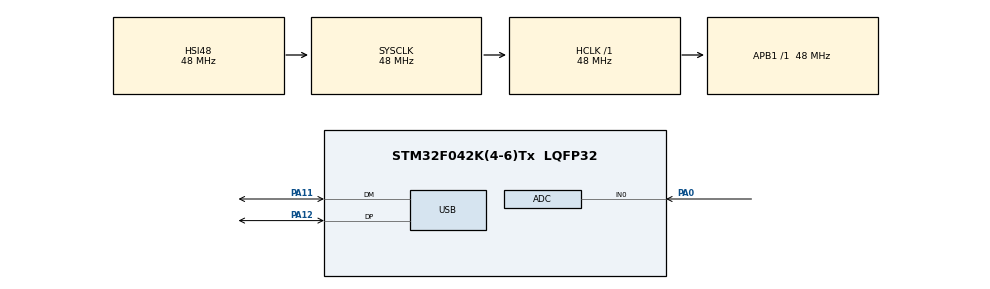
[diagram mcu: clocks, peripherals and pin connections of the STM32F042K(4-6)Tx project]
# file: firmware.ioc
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ADC.ContinuousConvMode=ENABLE
ADC.DMAContinuousRequests=ENABLE
ADC.SamplingTime=ADC_SAMPLETIME_71CYCLES_5
Dma.ADC.0.Direction=DMA_PERIPH_TO_MEMORY
Dma.ADC.0.Instance=DMA1_Channel1
Dma.ADC.0.MemDataAlignment=DMA_MDATAALIGN_HALFWORD
Dma.ADC.0.MemInc=DMA_MINC_ENABLE
Dma.ADC.0.Mode=DMA_CIRCULAR
Dma.ADC.0.PeriphDataAlignment=DMA_PDATAALIGN_HALFWORD
Dma.ADC.0.PeriphInc=DMA_PINC_DISABLE
Dma.ADC.0.Priority=DMA_PRIORITY_HIGH
Dma.Request0=ADC
Mcu.Family=STM32F0
Mcu.Name=STM32F042K(4-6)Tx
Mcu.Package=LQFP32
NVIC.DMA1_Channel1_IRQn=true\:0\:0\:false\:false\:true\:false\:true\:true
NVIC.USB_IRQn=true\:0\:0\:false\:false\:true\:false\:true\:true
PA0.Mode=IN0
PA0.Signal=ADC_IN0
PA11.Mode=Device
PA11.Signal=USB_DM
PA12.Mode=Device
PA12.Signal=USB_DP
PA13.Mode=Serial_Wire
PA13.Signal=SYS_SWDIO
PA14.Mode=Serial_Wire
PA14.Signal=SYS_SWCLK
ProjectManager.HeapSize=0x200
ProjectManager.StackSize=0x400
ProjectManager.TargetToolchain=STM32CubeIDE
RCC.AHBFreq_Value=48000000
RCC.APB1Freq_Value=48000000
RCC.APB1TimFreq_Value=48000000
RCC.HCLKFreq_Value=48000000
RCC.SYSCLKFreq_VALUE=48000000
RCC.SYSCLKSource=RCC_SYSCLKSOURCE_HSI48
USB_DEVICE.CLASS_NAME_FS=HID
USB_DEVICE.MANUFACTURER_STRING=emb3rcia
USB_DEVICE.PRODUCT_STRING_HID_FS=Turnsignals
USB_DEVICE.VirtualMode=Hid
USB_DEVICE.VirtualModeFS=Hid_FS
VP_USB_DEVICE_VS_USB_DEVICE_HID_FS.Mode=HID_FS
board=custom

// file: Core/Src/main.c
/* USER CODE BEGIN Header */
/**
  ******************************************************************************
  * @file           : main.c
  * @brief          : Main program body
  ******************************************************************************
  * @attention
  *
  * Copyright (c) 2026 STMicroelectronics.
  * All rights reserved.
  *
  * This software is licensed under terms that can be found in the LICENSE file
  * in the root directory of this software component.
  * If no LICENSE file comes with this software, it is provided AS-IS.
  *
  ******************************************************************************
  */
/* USER CODE END Header */
#include "main.h"
#include "usb_device.h"

ADC_HandleTypeDef hadc;
DMA_HandleTypeDef hdma_adc;

/* USER CODE BEGIN PV */
// i based this on chatgpt's example barebone code as it is my first stm32 project, but i did NOT copy it line for line, wanted to be transparent
#define ADC_LOW_THRESHOLD 1000
#define ADC_HIGH_THRESHOLD 3000
#define STABLE_COUNT 8
#define KEY_LOW 0x4F
#define KEY_HIGH 0x50

typedef enum {
	ADC_ZONE_MIDDLE = 0,
	ADC_ZONE_LOW,
	ADC_ZONE_HIGH
} adc_zone_t;

static adc_zone_t zone = ADC_ZONE_MIDDLE;
static uint8_t high_count = 0;
static uint8_t low_count  = 0;
static uint8_t middle_count = 0;

uint32_t value_adc;

/* USER CODE END PV */

void SystemClock_Config(void);
static void MX_GPIO_Init(void);
static void MX_DMA_Init(void);
static void MX_ADC_Init(void);

/* USER CODE BEGIN 0 */
void ADC_CheckZone(uint32_t adc)
{
	if (adc > ADC_HIGH_THRESHOLD)
	{
		high_count++;
		low_count = 0;
		middle_count = 0;

		if (high_count >= STABLE_COUNT && zone != ADC_ZONE_HIGH)
		{
			zone = ADC_ZONE_HIGH;
			high_count = 0;
			uint8_t HID_Report[8] = {0};
			HID_Report[2] = KEY_HIGH;
			USBD_HID_SendReport(&hUsbDeviceFS, HID_Report, sizeof(HID_Report));
		    HAL_Delay(10);
		    HID_Report[2] = 0;
		    USBD_HID_SendReport(&hUsbDeviceFS, HID_Report, sizeof(HID_Report));
		    HAL_Delay(10);
		}
	}
	else if (adc < ADC_LOW_THRESHOLD)
	{
		low_count++;
		high_count = 0;
		middle_count = 0;

		if (low_count >= STABLE_COUNT && zone != ADC_ZONE_LOW)
		{
			zone = ADC_ZONE_LOW;
			low_count = 0;
			uint8_t HID_Report[8] = {0};
			HID_Report[2] = KEY_LOW;
			USBD_HID_SendReport(&hUsbDeviceFS, HID_Report, sizeof(HID_Report));
		    HAL_Delay(10);
		    HID_Report[2] = 0;
		    USBD_HID_SendReport(&hUsbDeviceFS, HID_Report, sizeof(HID_Report));
		    HAL_Delay(10);
		}
	}
	else
	{
		middle_count++;
		high_count = 0;
		low_count = 0;

		if (middle_count >= STABLE_COUNT && zone != ADC_ZONE_MIDDLE)
		{
			if (zone == ADC_ZONE_HIGH)
			{
				uint8_t HID_Report[8] = {0};
				HID_Report[2] = KEY_HIGH;
				USBD_HID_SendReport(&hUsbDeviceFS, HID_Report, sizeof(HID_Report));
			    HAL_Delay(10);
			    HID_Report[2] = 0;
			    USBD_HID_SendReport(&hUsbDeviceFS, HID_Report, sizeof(HID_Report));
			    HAL_Delay(10);
			}
			else if (zone == ADC_ZONE_LOW)
			{
				uint8_t HID_Report[8] = {0};
				HID_Report[2] = KEY_LOW;
				USBD_HID_SendReport(&hUsbDeviceFS, HID_Report, sizeof(HID_Report));
				HAL_Delay(10);
				HID_Report[2] = 0;
				USBD_HID_SendReport(&hUsbDeviceFS, HID_Report, sizeof(HID_Report));
				HAL_Delay(10);
			}
			zone = ADC_ZONE_MIDDLE;
			middle_count = 0;

		}
	}
}
/* USER CODE END 0 */

int main(void)
{

  /* MCU Configuration--------------------------------------------------------*/

  /* Reset of all peripherals, Initializes the Flash interface and the Systick. */
  HAL_Init();

  /* Configure the system clock */
  SystemClock_Config();

  /* Initialize all configured peripherals */
  MX_GPIO_Init();
  MX_DMA_Init();
  MX_ADC_Init();
  MX_USB_DEVICE_Init();
  /* USER CODE BEGIN 2 */
  HAL_ADC_Start_DMA(&hadc, &value_adc, 1);
  /* USER CODE END 2 */

  /* Infinite loop */
  /* USER CODE BEGIN WHILE */
  while (1)
  {
	  ADC_CheckZone(value_adc);
	  HAL_Delay(10);
    /* USER CODE END WHILE */

  }
}

void SystemClock_Config(void)
{
  RCC_OscInitTypeDef RCC_OscInitStruct = {0};
  RCC_ClkInitTypeDef RCC_ClkInitStruct = {0};
  RCC_PeriphCLKInitTypeDef PeriphClkInit = {0};

  /** Initializes the RCC Oscillators according to the specified parameters
  * in the RCC_OscInitTypeDef structure.
  */
  RCC_OscInitStruct.OscillatorType = RCC_OSCILLATORTYPE_HSI14|RCC_OSCILLATORTYPE_HSI48;
  RCC_OscInitStruct.HSI48State = RCC_HSI48_ON;
  RCC_OscInitStruct.HSI14State = RCC_HSI14_ON;
  RCC_OscInitStruct.HSI14CalibrationValue = 16;
  RCC_OscInitStruct.PLL.PLLState = RCC_PLL_NONE;
  if (HAL_RCC_OscConfig(&RCC_OscInitStruct) != HAL_OK)
  {
    Error_Handler();
  }

  /** Initializes the CPU, AHB and APB buses clocks
  */
  RCC_ClkInitStruct.ClockType = RCC_CLOCKTYPE_HCLK|RCC_CLOCKTYPE_SYSCLK
                              |RCC_CLOCKTYPE_PCLK1;
  RCC_ClkInitStruct.SYSCLKSource = RCC_SYSCLKSOURCE_HSI48;
  RCC_ClkInitStruct.AHBCLKDivider = RCC_SYSCLK_DIV1;
  RCC_ClkInitStruct.APB1CLKDivider = RCC_HCLK_DIV1;

  if (HAL_RCC_ClockConfig(&RCC_ClkInitStruct, FLASH_LATENCY_1) != HAL_OK)
  {
    Error_Handler();
  }
  PeriphClkInit.PeriphClockSelection = RCC_PERIPHCLK_USB;
  PeriphClkInit.UsbClockSelection = RCC_USBCLKSOURCE_HSI48;

  if (HAL_RCCEx_PeriphCLKConfig(&PeriphClkInit) != HAL_OK)
  {
    Error_Handler();
  }
}

static void MX_ADC_Init(void)
{

  ADC_ChannelConfTypeDef sConfig = {0};

  /** Configure the global features of the ADC (Clock, Resolution, Data Alignment and number of conversion)
  */
  hadc.Instance = ADC1;
  hadc.Init.ClockPrescaler = ADC_CLOCK_ASYNC_DIV1;
  hadc.Init.Resolution = ADC_RESOLUTION_12B;
  hadc.Init.DataAlign = ADC_DATAALIGN_RIGHT;
  hadc.Init.ScanConvMode = ADC_SCAN_DIRECTION_FORWARD;
  hadc.Init.EOCSelection = ADC_EOC_SINGLE_CONV;
  hadc.Init.LowPowerAutoWait = DISABLE;
  hadc.Init.LowPowerAutoPowerOff = DISABLE;
  hadc.Init.ContinuousConvMode = ENABLE;
  hadc.Init.DiscontinuousConvMode = DISABLE;
  hadc.Init.ExternalTrigConv = ADC_SOFTWARE_START;
  hadc.Init.ExternalTrigConvEdge = ADC_EXTERNALTRIGCONVEDGE_NONE;
  hadc.Init.DMAContinuousRequests = ENABLE;
  hadc.Init.Overrun = ADC_OVR_DATA_PRESERVED;
  if (HAL_ADC_Init(&hadc) != HAL_OK)
  {
    Error_Handler();
  }

  /** Configure for the selected ADC regular channel to be converted.
  */
  sConfig.Channel = ADC_CHANNEL_0;
  sConfig.Rank = ADC_RANK_CHANNEL_NUMBER;
  sConfig.SamplingTime = ADC_SAMPLETIME_71CYCLES_5;
  if (HAL_ADC_ConfigChannel(&hadc, &sConfig) != HAL_OK)
  {
    Error_Handler();
  }

}

static void MX_DMA_Init(void)
{

  /* DMA controller clock enable */
  __HAL_RCC_DMA1_CLK_ENABLE();

  /* DMA interrupt init */
  /* DMA1_Channel1_IRQn interrupt configuration */
  HAL_NVIC_SetPriority(DMA1_Channel1_IRQn, 0, 0);
  HAL_NVIC_EnableIRQ(DMA1_Channel1_IRQn);

}

static void MX_GPIO_Init(void)
{

  /* GPIO Ports Clock Enable */
  __HAL_RCC_GPIOA_CLK_ENABLE();

}

void Error_Handler(void)
{
  __disable_irq();
  while (1)
  {
  }
}
